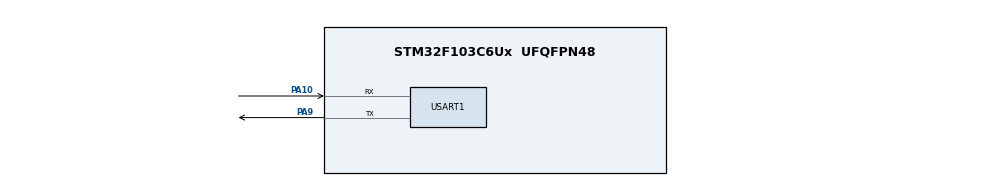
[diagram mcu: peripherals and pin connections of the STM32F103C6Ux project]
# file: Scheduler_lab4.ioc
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Mcu.Family=STM32F1
Mcu.Name=STM32F103C6Ux
Mcu.Package=UFQFPN48
NVIC.PriorityGroup=NVIC_PRIORITYGROUP_4
NVIC.TIM2_IRQn=true\:0\:0\:false\:false\:true\:true\:true
PA10.Mode=Asynchronous
PA10.Signal=USART1_RX
PA13.Mode=Serial_Wire
PA13.Signal=SYS_JTMS-SWDIO
PA14.Mode=Serial_Wire
PA14.Signal=SYS_JTCK-SWCLK
PA9.Mode=Asynchronous
PA9.Signal=USART1_TX
ProjectManager.HeapSize=0x200
ProjectManager.StackSize=0x400
ProjectManager.TargetToolchain=STM32CubeIDE
RCC.APB1Freq_Value=8000000
RCC.APB2Freq_Value=8000000
TIM2.Period=9
TIM2.Prescaler=7999
USART1.VirtualMode=VM_ASYNC
VP_TIM2_VS_ClockSourceINT.Mode=Internal
board=custom

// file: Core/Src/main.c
/* USER CODE BEGIN Header */
/**
  ******************************************************************************
  * @file           : main.c
  * @brief          : Main program body - Lab 4 Cooperative Scheduler
  ******************************************************************************
  */
/* USER CODE END Header */

#include "main.h"
#include "scheduler.h"
#include <stdio.h>

TIM_HandleTypeDef htim2;
UART_HandleTypeDef huart1;

/* USER CODE BEGIN PV */
// Bien dem so tick timer (1 tick = 10ms)
static volatile uint32_t system_ticks = 0;
/* USER CODE END PV */

void SystemClock_Config(void);
static void MX_TIM2_Init(void);
static void MX_GPIO_Init(void);
static void MX_USART1_UART_Init(void);

/* USER CODE BEGIN PFP */
uint32_t get_time(void);

void Task_Period_0_5s(void);
void Task_Period_1_0s(void);
void Task_Period_1_5s(void);
void Task_Period_2_0s(void);
void Task_Period_2_5s(void);
/* USER CODE END PFP */

/* USER CODE BEGIN 0 */

/**
 * @brief Chuyen huong printf xuat du lieu qua huart1
 */
int _write(int file, char *ptr, int len)
{
    HAL_UART_Transmit(&huart1, (uint8_t *)ptr, len, 50);
    return len;
}

/**
 * @brief Tra ve thoi gian he thong theo mili-giay (ms)
 */
uint32_t get_time(void)
{
    return system_ticks * 10;
}

/* Dinh nghia 5 tac vu tuan hoan theo de bai */
void Task_Period_0_5s(void)
{
    printf("[Timestamp: %lu ms] Task 1 (Period 0.5s) executed\r\n",
           (unsigned long)get_time());
}

void Task_Period_1_0s(void)
{
    printf("[Timestamp: %lu ms] Task 2 (Period 1.0s) executed\r\n",
           (unsigned long)get_time());
}

void Task_Period_1_5s(void)
{
    printf("[Timestamp: %lu ms] Task 3 (Period 1.5s) executed\r\n",
           (unsigned long)get_time());
}

void Task_Period_2_0s(void)
{
    printf("[Timestamp: %lu ms] Task 4 (Period 2.0s) executed\r\n",
           (unsigned long)get_time());
}

void Task_Period_2_5s(void)
{
    printf("[Timestamp: %lu ms] Task 5 (Period 2.5s) executed\r\n",
           (unsigned long)get_time());
}

/* USER CODE END 0 */

int main(void)
{
    /* MCU Configuration--------------------------------------------------------*/
    HAL_Init();
    SystemClock_Config();

    /* Initialize all configured peripherals */
    MX_GPIO_Init();
    MX_TIM2_Init();
    MX_USART1_UART_Init();

    /* USER CODE BEGIN 2 */
    SCH_Init();

    // In test duong truyen UART ngay khi khoi dong
    printf("\r\n========================================\r\n");
    printf("  SYSTEM START: LAB 4 COOPERATIVE SCHEDULER\r\n");
    printf("========================================\r\n");

    // Dang ky 5 tac vu
    // 0.5s (50 ticks), 1.0s (100 ticks),
    // 1.5s (150 ticks), 2.0s (200 ticks), 2.5s (250 ticks)

    SCH_Add_Task(Task_Period_0_5s, 50, 50);
    SCH_Add_Task(Task_Period_1_0s, 101, 100);
    SCH_Add_Task(Task_Period_1_5s, 152, 150);
    SCH_Add_Task(Task_Period_2_0s, 203, 200);
    SCH_Add_Task(Task_Period_2_5s, 254, 250);

    HAL_TIM_Base_Start_IT(&htim2);

    /* USER CODE END 2 */

    /* Infinite loop */
    while (1)
    {

        /* USER CODE BEGIN 3 */
        SCH_Dispatch_Tasks();
    }
    /* USER CODE END 3 */
}

void SystemClock_Config(void)
{
    RCC_OscInitTypeDef RCC_OscInitStruct = {0};
    RCC_ClkInitTypeDef RCC_ClkInitStruct = {0};

    RCC_OscInitStruct.OscillatorType = RCC_OSCILLATORTYPE_HSI;
    RCC_OscInitStruct.HSIState = RCC_HSI_ON;
    RCC_OscInitStruct.HSICalibrationValue = RCC_HSICALIBRATION_DEFAULT;
    RCC_OscInitStruct.PLL.PLLState = RCC_PLL_NONE;

    if (HAL_RCC_OscConfig(&RCC_OscInitStruct) != HAL_OK)
    {
        Error_Handler();
    }

    RCC_ClkInitStruct.ClockType = RCC_CLOCKTYPE_HCLK | RCC_CLOCKTYPE_SYSCLK
                                | RCC_CLOCKTYPE_PCLK1 | RCC_CLOCKTYPE_PCLK2;
    RCC_ClkInitStruct.SYSCLKSource = RCC_SYSCLKSOURCE_HSI;
    RCC_ClkInitStruct.AHBCLKDivider = RCC_SYSCLK_DIV1;
    RCC_ClkInitStruct.APB1CLKDivider = RCC_HCLK_DIV1;
    RCC_ClkInitStruct.APB2CLKDivider = RCC_HCLK_DIV1;

    if (HAL_RCC_ClockConfig(&RCC_ClkInitStruct, FLASH_LATENCY_0) != HAL_OK)
    {
        Error_Handler();
    }
}

static void MX_TIM2_Init(void)
{
    TIM_ClockConfigTypeDef sClockSourceConfig = {0};
    TIM_MasterConfigTypeDef sMasterConfig = {0};

    htim2.Instance = TIM2;
    htim2.Init.Prescaler = 7999;
    htim2.Init.CounterMode = TIM_COUNTERMODE_UP;
    htim2.Init.Period = 9;
    htim2.Init.ClockDivision = TIM_CLOCKDIVISION_DIV1;
    htim2.Init.AutoReloadPreload = TIM_AUTORELOAD_PRELOAD_DISABLE;

    if (HAL_TIM_Base_Init(&htim2) != HAL_OK)
    {
        Error_Handler();
    }

    sClockSourceConfig.ClockSource = TIM_CLOCKSOURCE_INTERNAL;

    if (HAL_TIM_ConfigClockSource(&htim2, &sClockSourceConfig) != HAL_OK)
    {
        Error_Handler();
    }

    sMasterConfig.MasterOutputTrigger = TIM_TRGO_RESET;
    sMasterConfig.MasterSlaveMode = TIM_MASTERSLAVEMODE_DISABLE;

    if (HAL_TIMEx_MasterConfigSynchronization(&htim2, &sMasterConfig) != HAL_OK)
    {
        Error_Handler();
    }
}

static void MX_USART1_UART_Init(void)
{
    huart1.Instance = USART1;
    huart1.Init.BaudRate = 115200;
    huart1.Init.WordLength = UART_WORDLENGTH_8B;
    huart1.Init.StopBits = UART_STOPBITS_1;
    huart1.Init.Parity = UART_PARITY_NONE;
    huart1.Init.Mode = UART_MODE_TX_RX;
    huart1.Init.HwFlowCtl = UART_HWCONTROL_NONE;
    huart1.Init.OverSampling = UART_OVERSAMPLING_16;

    if (HAL_UART_Init(&huart1) != HAL_OK)
    {
        Error_Handler();
    }
}

static void MX_GPIO_Init(void)
{
    __HAL_RCC_GPIOA_CLK_ENABLE();
}

/* USER CODE BEGIN 4 */
void HAL_TIM_PeriodElapsedCallback(TIM_HandleTypeDef *htim)
{
    if (htim->Instance == TIM2)
    {
        system_ticks++;
        SCH_Update();
    }
}
/* USER CODE END 4 */

void Error_Handler(void)
{
    __disable_irq();
    while (1)
    {
    }
}
